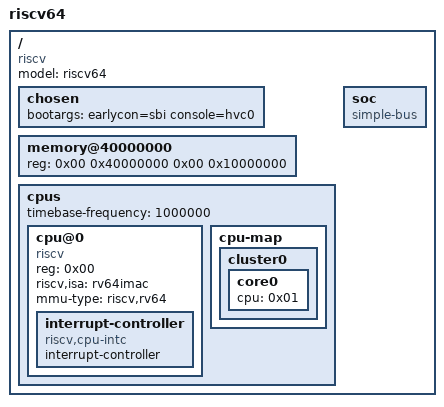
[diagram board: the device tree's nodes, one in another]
/dts-v1/;

/ {
	#address-cells = <0x02>;
	#size-cells = <0x02>;
	compatible = "riscv";
	model = "riscv64";

	chosen {
		bootargs = "earlycon=sbi console=hvc0";
	};

	memory@40000000 {
		device_type = "memory";
		reg = <0x00 0x40000000 0x00 0x10000000>;
	};

	cpus {
		#address-cells = <0x01>;
		#size-cells = <0x00>;
		timebase-frequency = <1000000>;

		cpu@0 {
			device_type = "cpu";
			reg = <0x00>;
			compatible = "riscv";
			riscv,isa = "rv64imac";
			mmu-type = "riscv,rv64";
			status = "okay";
			phandle = <0x01>;

			interrupt-controller {
				#interrupt-cells = <0x01>;
				interrupt-controller;
				compatible = "riscv,cpu-intc";
				phandle = <0x02>;
			};
		};

		cpu-map {

			cluster0 {

				core0 {
					cpu = <0x01>;
				};
			};
		};
	};

	soc {
		#address-cells = <0x02>;
		#size-cells = <0x02>;
		compatible = "simple-bus";
		ranges;
	};
};
